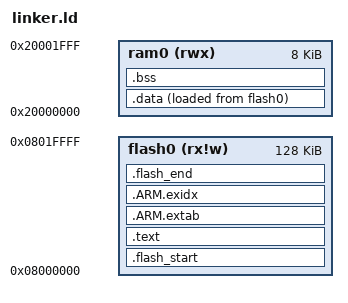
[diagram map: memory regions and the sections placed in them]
/*
 * Target CPU:  cortex_m3
 * Target Chip: STM32F100RB
 */

/*
 * This section was auto-generated by microzig.
 */
MEMORY
{
  flash0 (rx!w) : ORIGIN = 0x08000000, LENGTH = 0x00020000
  ram0 (rwx) : ORIGIN = 0x20000000, LENGTH = 0x00002000
}
SECTIONS
{
  .flash_start :
  {
    KEEP(*(microzig_flash_start))
  } > flash0

  .text :
  {
    *(.text*)
    *(.srodata*)
    *(.rodata*)
  } > flash0

  .ARM.extab : {
    *(.ARM.extab* .gnu.linkonce.armextab.*)
  } > flash0

  .ARM.exidx : {
    *(.ARM.exidx* .gnu.linkonce.armexidx.*)
  } > flash0

  .data :
  {
    microzig_data_start = .;
    *(.sdata*)
    *(.data*)
    KEEP(*(.ram_text))
    microzig_data_end = .;
  } > ram0 AT> flash0

  .bss (NOLOAD) :
  {
    microzig_bss_start = .;
    *(.sbss*)
    *(.bss*)
    microzig_bss_end = .;
  } > ram0

  .flash_end :
  {
    microzig_flash_end = .;
  } > flash0

  microzig_data_load_start = LOADADDR(.data);
}
/*
 * End of auto-generated section.
 */
